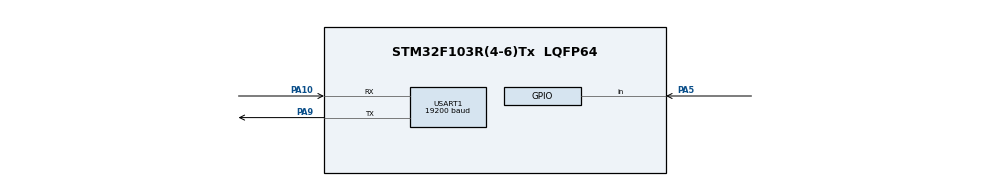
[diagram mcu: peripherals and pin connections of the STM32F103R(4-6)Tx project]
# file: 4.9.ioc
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Mcu.Family=STM32F1
Mcu.Name=STM32F103R(4-6)Tx
Mcu.Package=LQFP64
NVIC.PriorityGroup=NVIC_PRIORITYGROUP_4
NVIC.USART1_IRQn=true\:0\:0\:false\:false\:true\:true\:true
PA10.Mode=Asynchronous
PA10.Signal=USART1_RX
PA5.GPIO_PuPd=GPIO_PULLUP
PA5.Signal=GPIO_Input
PA9.Mode=Asynchronous
PA9.Signal=USART1_TX
ProjectManager.HeapSize=0x200
ProjectManager.StackSize=0x400
ProjectManager.TargetToolchain=STM32CubeIDE
RCC.APB1Freq_Value=8000000
RCC.APB2Freq_Value=8000000
USART1.BaudRate=19200
USART1.VirtualMode=VM_ASYNC
VP_SYS_VS_ND.Mode=No_Debug
board=custom

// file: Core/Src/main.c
/* USER CODE BEGIN Header */
/**
  ******************************************************************************
  * @file           : main.c
  * @brief          : Main program body
  ******************************************************************************
  * @attention
  *
  * <h2><center>&copy; Copyright (c) 2020 STMicroelectronics.
  * All rights reserved.</center></h2>
  *
  * This software component is licensed by ST under BSD 3-Clause license,
  * the "License"; You may not use this file except in compliance with the
  * License. You may obtain a copy of the License at:
  *                        opensource.org/licenses/BSD-3-Clause
  *
  ******************************************************************************
  */
/* USER CODE END Header */

#include "main.h"

/* USER CODE BEGIN PM */
#define _FLASH_ADD 0x08006400
/* USER CODE END PM */

UART_HandleTypeDef huart1;

/* USER CODE BEGIN PV */
uint8_t rf=0;
uint8_t RcvBuf[1];
uint8_t SndBuf[1];
/* USER CODE END PV */

void SystemClock_Config(void);
static void MX_GPIO_Init(void);
static void MX_USART1_UART_Init(void);
/* USER CODE BEGIN PFP */
void FlashErase(uint32_t Add);
void FlashWrite(uint32_t Add,uint16_t Dat);
uint16_t FlashRead(uint32_t Add);
/* USER CODE END PFP */

int main(void)
{
  /* USER CODE BEGIN 1 */
	uint16_t flash_wdat=0xabcd;
  /* USER CODE END 1 */

  /* MCU Configuration--------------------------------------------------------*/

  /* Reset of all peripherals, Initializes the Flash interface and the Systick. */
  HAL_Init();

  /* Configure the system clock */
  SystemClock_Config();

  /* Initialize all configured peripherals */
  MX_GPIO_Init();
  MX_USART1_UART_Init();
  /* USER CODE BEGIN 2 */
  HAL_UART_Receive_IT(&huart1,RcvBuf,1);
  /* USER CODE END 2 */

  /* Infinite loop */
  /* USER CODE BEGIN WHILE */
  while (1)
  {
	  if(rf==1)
	  {
		  rf=0;
		  flash_wdat=RcvBuf[0];
		  FlashErase(_FLASH_ADD);
		  FlashWrite(_FLASH_ADD,flash_wdat);
		  HAL_UART_Receive_IT(&huart1,RcvBuf,1);
	  }
	  if(HAL_GPIO_ReadPin(GPIOA,GPIO_PIN_5)==GPIO_PIN_RESET)
	  {
		  HAL_Delay(25);
		  if(HAL_GPIO_ReadPin(GPIOA,GPIO_PIN_5)==GPIO_PIN_RESET)
		  {
			  SndBuf[0]=(uint8_t)FlashRead(_FLASH_ADD);
			  HAL_UART_Transmit(&huart1,SndBuf,1,10);
			  while(HAL_GPIO_ReadPin(GPIOA,GPIO_PIN_5)==GPIO_PIN_RESET);
		  }
	  }
    /* USER CODE END WHILE */

  }
}

void SystemClock_Config(void)
{
  RCC_OscInitTypeDef RCC_OscInitStruct = {0};
  RCC_ClkInitTypeDef RCC_ClkInitStruct = {0};

  /** Initializes the CPU, AHB and APB busses clocks
  */
  RCC_OscInitStruct.OscillatorType = RCC_OSCILLATORTYPE_HSI;
  RCC_OscInitStruct.HSIState = RCC_HSI_ON;
  RCC_OscInitStruct.HSICalibrationValue = RCC_HSICALIBRATION_DEFAULT;
  RCC_OscInitStruct.PLL.PLLState = RCC_PLL_NONE;
  if (HAL_RCC_OscConfig(&RCC_OscInitStruct) != HAL_OK)
  {
    Error_Handler();
  }
  /** Initializes the CPU, AHB and APB busses clocks
  */
  RCC_ClkInitStruct.ClockType = RCC_CLOCKTYPE_HCLK|RCC_CLOCKTYPE_SYSCLK
                              |RCC_CLOCKTYPE_PCLK1|RCC_CLOCKTYPE_PCLK2;
  RCC_ClkInitStruct.SYSCLKSource = RCC_SYSCLKSOURCE_HSI;
  RCC_ClkInitStruct.AHBCLKDivider = RCC_SYSCLK_DIV1;
  RCC_ClkInitStruct.APB1CLKDivider = RCC_HCLK_DIV1;
  RCC_ClkInitStruct.APB2CLKDivider = RCC_HCLK_DIV1;

  if (HAL_RCC_ClockConfig(&RCC_ClkInitStruct, FLASH_LATENCY_0) != HAL_OK)
  {
    Error_Handler();
  }
}

static void MX_USART1_UART_Init(void)
{

  huart1.Instance = USART1;
  huart1.Init.BaudRate = 19200;
  huart1.Init.WordLength = UART_WORDLENGTH_8B;
  huart1.Init.StopBits = UART_STOPBITS_1;
  huart1.Init.Parity = UART_PARITY_NONE;
  huart1.Init.Mode = UART_MODE_TX_RX;
  huart1.Init.HwFlowCtl = UART_HWCONTROL_NONE;
  huart1.Init.OverSampling = UART_OVERSAMPLING_16;
  if (HAL_UART_Init(&huart1) != HAL_OK)
  {
    Error_Handler();
  }

}

static void MX_GPIO_Init(void)
{
  GPIO_InitTypeDef GPIO_InitStruct = {0};

  /* GPIO Ports Clock Enable */
  __HAL_RCC_GPIOA_CLK_ENABLE();

  /*Configure GPIO pin : PA5 */
  GPIO_InitStruct.Pin = GPIO_PIN_5;
  GPIO_InitStruct.Mode = GPIO_MODE_INPUT;
  GPIO_InitStruct.Pull = GPIO_PULLUP;
  HAL_GPIO_Init(GPIOA, &GPIO_InitStruct);

}

/* USER CODE BEGIN 4 */
void HAL_UART_RxCpltCallback (UART_HandleTypeDef *huart)
{
	if(huart==&huart1)
	{
		rf=1;
	}
}

/****************************************************
Flash页擦除
Add--待擦除页的首地址
Flash必须整页擦除，也就是整页的每个地址单元内容均为FFH才能写入新数据
****************************************************/
void FlashErase(uint32_t Add)
{
  uint32_t  page_error = 0;
  FLASH_EraseInitTypeDef erase_initstruct =
  {
   .TypeErase = FLASH_TYPEERASE_PAGES,/* 擦除方式—�?�页擦除*/
   .NbPages = 1,/* 页数量�?��?�单�??? */
   .PageAddress = Add /* 擦除页起始地�??? */
  };
  HAL_FLASH_Unlock();
  HAL_FLASHEx_Erase(&erase_initstruct,&page_error); //擦除
  HAL_FLASH_Lock();
}

/****************************************************
Flash写函�???
写入1个Half Word�???16位）型数�???
Add--Flash Address; Dat--Kept Data(2Bytes)
注意：写入时，高字节在高地址
****************************************************/
void FlashWrite(uint32_t Add,uint16_t Dat)
{
  HAL_FLASH_Unlock();
  HAL_FLASH_Program(FLASH_TYPEPROGRAM_HALFWORD, Add, Dat);
  HAL_FLASH_Lock();
}

//Flash读函数，返回�???个Half Word�???16位）型数�???
//Add--Flash Address;
uint16_t FlashRead(uint32_t Add)
{
  uint16_t dat;
  dat = *(uint16_t *)Add;
  return dat;
}

/* USER CODE END 4 */

void Error_Handler(void)
{
}

/************************ (C) COPYRIGHT STMicroelectronics *****END OF FILE****/
